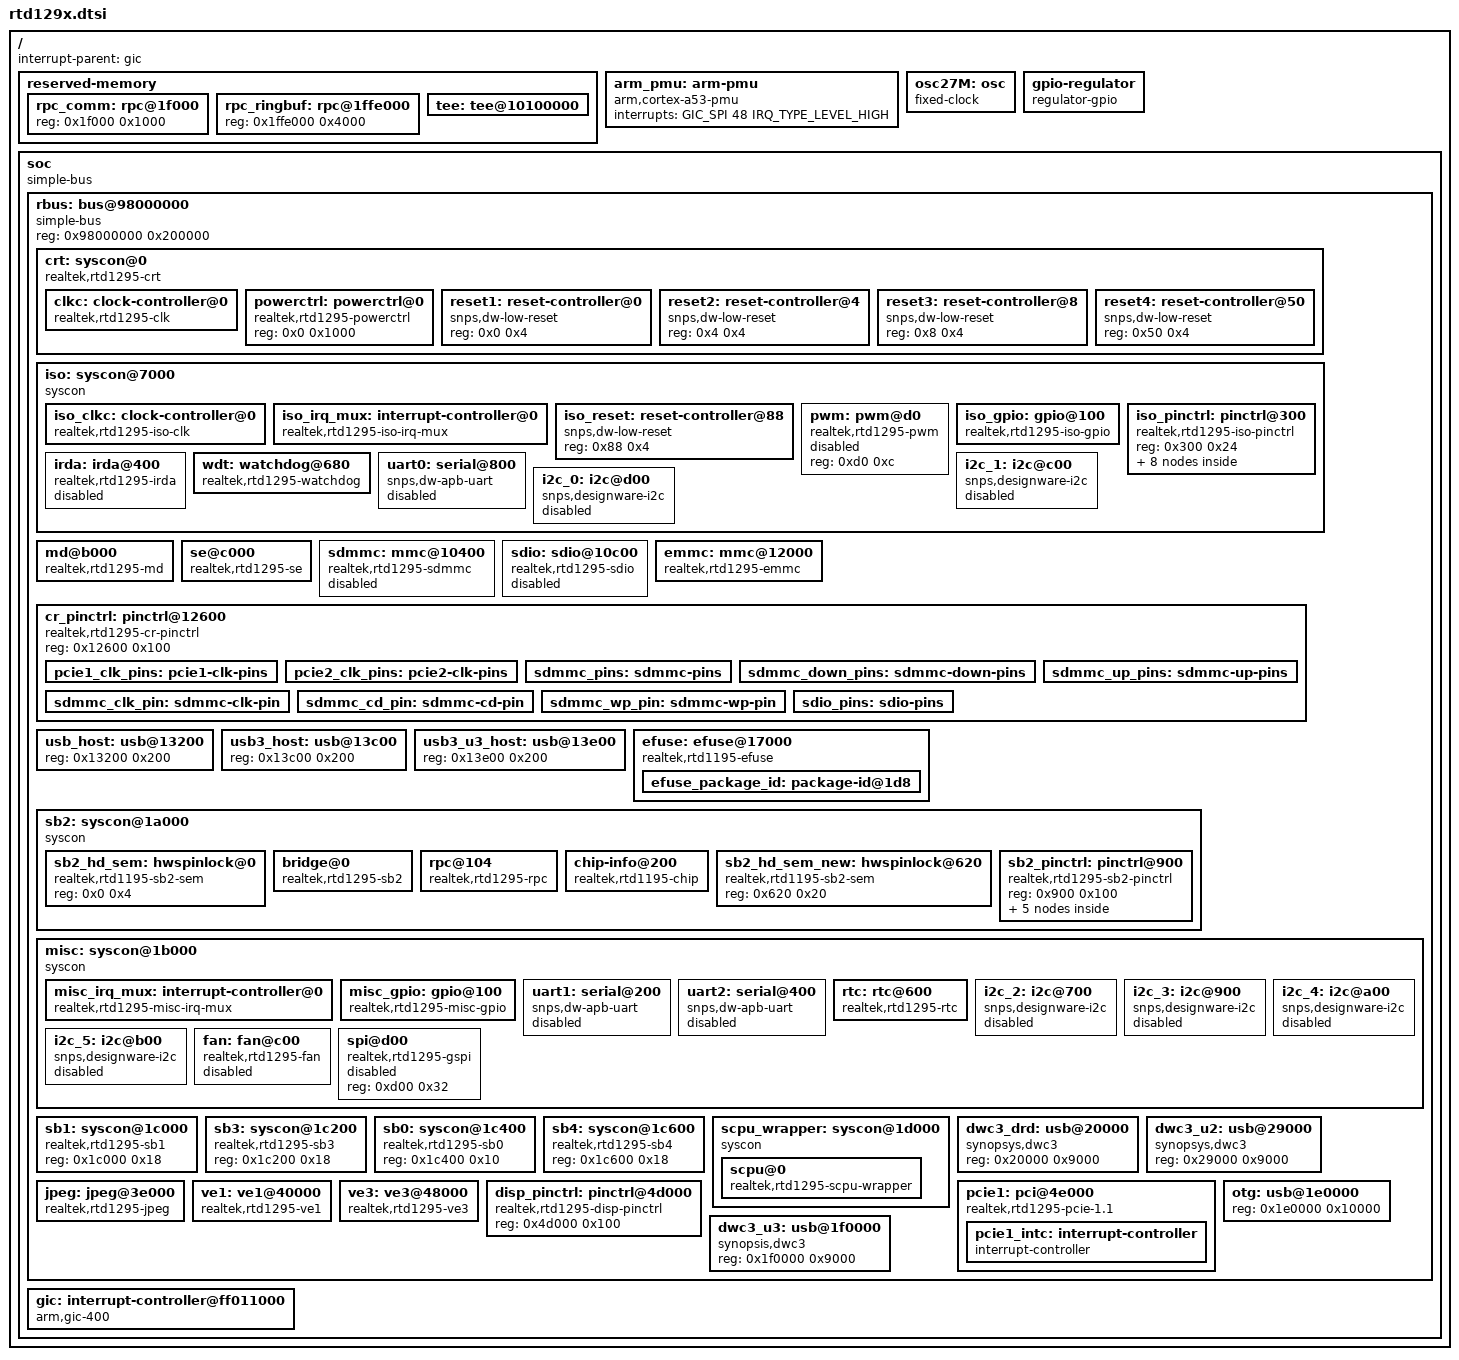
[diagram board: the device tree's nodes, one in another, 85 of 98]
// SPDX-License-Identifier: (GPL-2.0-or-later OR BSD-2-Clause)
/*
 * Realtek RTD1293/RTD1295/RTD1296 SoC
 *
 * Copyright (c) 2016-2019 Andreas Färber
 */

/memreserve/	0x0000000000000000 0x000000000001f000;
/memreserve/	0x000000000001f000 0x00000000000e1000;
/memreserve/	0x0000000001b00000 0x00000000004be000;

#include <dt-bindings/clock/realtek,rtd1295.h>
#include <dt-bindings/gpio/gpio.h>
#include <dt-bindings/interrupt-controller/arm-gic.h>
#include <dt-bindings/reset/realtek,rtd1295.h>

/ {
	interrupt-parent = <&gic>;
	#address-cells = <1>;
	#size-cells = <1>;

	reserved-memory {
		#address-cells = <1>;
		#size-cells = <1>;
		ranges;

		rpc_comm: rpc@1f000 {
			reg = <0x1f000 0x1000>;
		};

		rpc_ringbuf: rpc@1ffe000 {
			reg = <0x1ffe000 0x4000>;
		};

		tee: tee@10100000 {
			reg = <0x10100000 0xf00000>;
			no-map;
		};
	};

	arm_pmu: arm-pmu {
		compatible = "arm,cortex-a53-pmu";
		interrupts = <GIC_SPI 48 IRQ_TYPE_LEVEL_HIGH>;
	};

	osc27M: osc {
		compatible = "fixed-clock";
		clock-frequency = <27000000>;
		#clock-cells = <0>;
		clock-output-names = "osc27M";
	};

	gpio-regulator {
		compatible = "regulator-gpio";
		regulator-type = "voltage";
		regulator-name = "gpio-regulator";
		regulator-min-microvolt = < 850000>;
		regulator-max-microvolt = <1050000>;
		regulator-boot-on;
		regulator-always-on;
		gpios = <&iso_gpio 16 GPIO_ACTIVE_HIGH>,
			<&iso_gpio 17 GPIO_ACTIVE_HIGH>;
		gpios-states = <0>, <1>;
		enable-active-high;
		states = < 850000 0>,
			 < 950000 2>,
			 <1050000 3>;
	};

	soc {
		compatible = "simple-bus";
		#address-cells = <1>;
		#size-cells = <1>;
		ranges = <0x00000000 0x00000000 0x0001f000>, /* boot ROM */
			 <0x00030000 0x00030000 0x00020000>, /* PCIe IO */
			 /* Exclude up to 2 GiB of RAM */
			 <0x80000000 0x80000000 0x80000000>;

		rbus: bus@98000000 {
			compatible = "simple-bus";
			reg = <0x98000000 0x200000>;
			#address-cells = <1>;
			#size-cells = <1>;
			ranges = <0x00000000 0x98000000 0x00200000>,
				 <0xc0000000 0xc0000000 0x02000000>, /* PCIe */
				 <0x10030000 0x00030000 0x00020000>; /* PCIe */

			crt: syscon@0 {
				compatible = "realtek,rtd1295-crt", "syscon", "simple-mfd";
				reg = <0x0 0x1800>;
				reg-io-width = <4>;
				#address-cells = <1>;
				#size-cells = <1>;
				ranges = <0x0 0x0 0x1800>;
			};

			iso: syscon@7000 {
				compatible = "syscon", "simple-mfd";
				reg = <0x7000 0x1000>;
				reg-io-width = <4>;
				#address-cells = <1>;
				#size-cells = <1>;
				ranges = <0x0 0x7000 0x1000>;
			};

			md@b000 {
				compatible = "realtek,rtd1295-md";
				reg = <0xb000 0x1000>;
				interrupts = <GIC_SPI 38 IRQ_TYPE_LEVEL_HIGH>;
			};

			se@c000 {
				compatible = "realtek,rtd1295-se";
				reg = <0xc000 0x1000>;
				interrupts = <GIC_SPI 20 IRQ_TYPE_LEVEL_HIGH>;
			};

			sdmmc: mmc@10400 {
				compatible = "realtek,rtd1295-sdmmc";
				reg = <0x10400 0x200>;
				crt-syscon = <&crt>;
				sb2-syscon = <&sb2>;
				pinctrl-names = "default", "card";
				pinctrl-0 = <&sdmmc_pins>, <&sdmmc_down_pins>, <&sdmmc_clk_pin>, <&sdmmc_cd_pin>, <&sdmmc_wp_pin>;
				pinctrl-1 = <&sdmmc_pins>, <&sdmmc_up_pins>, <&sdmmc_clk_pin>, <&sdmmc_cd_pin>, <&sdmmc_wp_pin>;
				interrupts = <GIC_SPI 44 IRQ_TYPE_LEVEL_HIGH>;
				resets = <&reset2 RTD1295_RSTN_CR>;
				clocks = <&clkc RTD1295_CLK_EN_CR>, <&clkc RTD1295_CLK_EN_SD_IP>;
				clock-names = "clk_en_cr", "clk_en_sd_ip";
				cap-mmc-highspeed;
				cap-sd-highspeed;
				cap-mmc-hw-reset;
				no-sdio;
				sd-uhs-sdr12;
				sd-uhs-sdr25;
				sd-uhs-sdr50;
				sd-uhs-sdr104;
				status = "disabled";
			};

			sdio: sdio@10c00 {
				compatible = "realtek,rtd1295-sdio";
				reg = <0x10c00 0x100>,
				      <0x10a00 0x100>; /* wrapper */
				crt-syscon = <&crt>;
				pinctrl-names = "default";
				pinctrl-0 = <&sdio_pins>;
				interrupts = <GIC_SPI 45 IRQ_TYPE_LEVEL_HIGH>;
				resets = <&reset2 RTD1295_RSTN_SDIO>;
				clocks = <&clkc RTD1295_CLK_EN_SDIO>, <&clkc RTD1295_CLK_EN_SDIO_IP>;
				clock-names = "clk_en_sdio", "clk_en_sdio_ip";
				cap-mmc-highspeed;
				cap-sd-highspeed;
				cap-sdio-irq;
				no-mmc;
				no-sd;
				sd-uhs-sdr12;
				sd-uhs-sdr25;
				sd-uhs-sdr50;
				sd-uhs-sdr104;
				status = "disabled";
			};

			emmc: mmc@12000 {
				compatible = "realtek,rtd1295-emmc";
				reg = <0x12000 0xa00>;
				interrupts = <GIC_SPI 42 IRQ_TYPE_LEVEL_HIGH>;
			};

			cr_pinctrl: pinctrl@12600 {
				compatible = "realtek,rtd1295-cr-pinctrl";
				reg = <0x12600 0x100>;
			};

			usb_host: usb@13200 {
				reg = <0x13200 0x200>;
			};

			usb3_host: usb@13c00 {
				reg = <0x13c00 0x200>;
			};

			usb3_u3_host: usb@13e00 {
				reg = <0x13e00 0x200>;
			};

			efuse: efuse@17000 {
				compatible = "realtek,rtd1195-efuse";
				reg = <0x17000 0x400>;
				read-only;
				#address-cells = <1>;
				#size-cells = <1>;
			};

			sb2: syscon@1a000 {
				compatible = "syscon", "simple-mfd";
				reg = <0x1a000 0x1000>;
				reg-io-width = <4>;
				#address-cells = <1>;
				#size-cells = <1>;
				ranges = <0x0 0x1a000 0x1000>;
			};

			misc: syscon@1b000 {
				compatible = "syscon", "simple-mfd";
				reg = <0x1b000 0x1000>;
				reg-io-width = <4>;
				#address-cells = <1>;
				#size-cells = <1>;
				ranges = <0x0 0x1b000 0x1000>;
			};

			sb1: syscon@1c000 {
				compatible = "realtek,rtd1295-sb1";
				reg = <0x1c000 0x18>;
			};

			sb3: syscon@1c200 {
				compatible = "realtek,rtd1295-sb3";
				reg = <0x1c200 0x18>;
			};

			sb0: syscon@1c400 {
				compatible = "realtek,rtd1295-sb0";
				reg = <0x1c400 0x10>;
			};

			sb4: syscon@1c600 {
				compatible = "realtek,rtd1295-sb4", "syscon";
				reg = <0x1c600 0x18>;
			};

			scpu_wrapper: syscon@1d000 {
				compatible = "syscon", "simple-mfd";
				reg = <0x1d000 0x2000>;
				reg-io-width = <4>;
				#address-cells = <1>;
				#size-cells = <1>;
				ranges = <0x0 0x1d000 0x2000>;
			};

			dwc3_drd: usb@20000 {
				compatible = "synopsys,dwc3";
				reg = <0x20000 0x9000>;
			};

			dwc3_u2: usb@29000 {
				compatible = "synopsys,dwc3";
				reg = <0x29000 0x9000>;
			};

			jpeg: jpeg@3e000 {
				compatible = "realtek,rtd1295-jpeg";
				reg = <0x3e000 0x1000>;
				interrupts = <GIC_SPI 52 IRQ_TYPE_LEVEL_HIGH>;
			};

			ve1: ve1@40000 {
				compatible = "realtek,rtd1295-ve1";
				reg = <0x40000 0x8000>;
				interrupts = <GIC_SPI 53 IRQ_TYPE_LEVEL_HIGH>,
				             <GIC_SPI 54 IRQ_TYPE_LEVEL_HIGH>;
			};

			ve3: ve3@48000 {
				compatible = "realtek,rtd1295-ve3";
				reg = <0x48000 0x4000>;
				interrupts = <GIC_SPI 55 IRQ_TYPE_LEVEL_HIGH>;
			};

			disp_pinctrl: pinctrl@4d000 {
				compatible = "realtek,rtd1295-disp-pinctrl";
				reg = <0x4d000 0x100>;
			};

			pcie1: pci@4e000 {
				device_type = "pci";
				compatible = "realtek,rtd1295-pcie-1.1";
				reg = <0x4e000 0x1000>,
				      <0x4f000 0x1000>,
				      <0xc0000000 0x01000000>;
				pinctrl-names = "default";
				pinctrl-0 = <&pcie1_clk_pins>;
				sb4-syscon = <&sb4>;
				clocks = <&clkc RTD1295_CLK_EN_PCIE0>;
				resets = <&reset2 RTD1295_RSTN_PCIE0>,
					 <&reset2 RTD1295_RSTN_PCIE0_CORE>,
					 <&reset2 RTD1295_RSTN_PCIE0_POWER>,
					 <&reset2 RTD1295_RSTN_PCIE0_STITCH>,
					 <&reset2 RTD1295_RSTN_PCIE0_NONSTICH>,
					 <&reset2 RTD1295_RSTN_PCIE0_PHY>,
					 <&reset4 RTD1295_RSTN_PCIE0_PHY_MDIO>;
				reset-names = "pcie",
					      "pcie_core",
					      "pcie_power",
					      "pcie_stitch",
					      "pcie_nonstitch",
					      "pcie_phy",
					      "pcie_phy_mdio";
				reset-gpios = <&misc_gpio 18 GPIO_ACTIVE_LOW>;
				interrupts = <GIC_SPI 61 IRQ_TYPE_LEVEL_HIGH>;
				#interrupt-cells = <1>;
				interrupt-map-mask = <0 0 0 7>;
				interrupt-map = <0 0 0 1 &pcie1_intc 0>,
						<0 0 0 2 &pcie1_intc 1>,
						<0 0 0 3 &pcie1_intc 2>,
						<0 0 0 4 &pcie1_intc 3>;
				bus-range = <0x00 0xff>;
				num-lanes = <1>;
				max-link-speed = <1>;
				linux,pci-domain = <0>;
				#address-cells = <3>;
				#size-cells = <2>;
				ranges = <0x02000000 0x00000000 0xc0000000  0xc0000000  0x00000000 0x00001000>,
					 <0x01000000 0x00000000 0x00030000  0x10030000  0x00000000 0x00010000>;

				pcie1_intc: interrupt-controller {
					interrupt-controller;
					#interrupt-cells = <1>;
				};
			};

			otg: usb@1e0000 {
				reg = <0x1e0000 0x10000>;
			};

			dwc3_u3: usb@1f0000 {
				compatible = "synopsis,dwc3";
				reg = <0x1f0000 0x9000>;
			};
		};

		gic: interrupt-controller@ff011000 {
			compatible = "arm,gic-400";
			reg = <0xff011000 0x1000>,
			      <0xff012000 0x2000>,
			      <0xff014000 0x2000>,
			      <0xff016000 0x2000>;
			interrupts = <GIC_PPI 9 (GIC_CPU_MASK_SIMPLE(4) | IRQ_TYPE_LEVEL_LOW)>;
			interrupt-controller;
			#interrupt-cells = <3>;
		};
	};
};

&cr_pinctrl {
	pcie1_clk_pins: pcie1-clk-pins {
		function = "pcie";
		pins = "pcie_clkreq_0";
	};

	pcie2_clk_pins: pcie2-clk-pins {
		function = "pcie";
		pins = "pcie_clkreq_1";
	};

	sdmmc_pins: sdmmc-pins {
		function = "sd_card";
		groups = "mmc_cmd", "mmc_data_0", "mmc_data_1", "mmc_data_2", "mmc_data_3";
	};

	sdmmc_down_pins: sdmmc-down-pins {
		pins = "mmc_cmd", "mmc_data_0", "mmc_data_1", "mmc_data_2", "mmc_data_3";
		bias-pull-down;
	};

	sdmmc_up_pins: sdmmc-up-pins {
		pins = "mmc_cmd", "mmc_data_0", "mmc_data_1", "mmc_data_2", "mmc_data_3";
		bias-pull-up;
	};

	sdmmc_clk_pin: sdmmc-clk-pin {
		pins = "mmc_clk";
		function = "sd_card";
		bias-pull-down;
	};

	sdmmc_cd_pin: sdmmc-cd-pin {
		function = "sd_card";
		groups = "mmc_cd";
		bias-pull-up;
		drive-strength = <4>;
	};

	sdmmc_wp_pin: sdmmc-wp-pin {
		function = "sd_card";
		groups = "mmc_wp";
		bias-pull-up;
		drive-strength = <4>;
	};

	sdio_pins: sdio-pins {
		function = "sdio_0";
		groups = "sdio_cmd", "sdio_clk", "sdio_data_0", "sdio_data_1", "sdio_data_2", "sdio_data_3";
	};
};

&crt {
	clkc: clock-controller@0 {
		compatible = "realtek,rtd1295-clk";
		reg = <0x0 0x1000>;
		clocks = <&osc27M>;
		#clock-cells = <1>;
	};

	powerctrl: powerctrl@0 {
		compatible = "realtek,rtd1295-powerctrl";
		reg = <0x0 0x1000>;
		#power-domain-cells = <1>;
	};

	reset1: reset-controller@0 {
		compatible = "snps,dw-low-reset";
		reg = <0x0 0x4>;
		#reset-cells = <1>;
	};

	reset2: reset-controller@4 {
		compatible = "snps,dw-low-reset";
		reg = <0x4 0x4>;
		#reset-cells = <1>;
	};

	reset3: reset-controller@8 {
		compatible = "snps,dw-low-reset";
		reg = <0x8 0x4>;
		#reset-cells = <1>;
	};

	reset4: reset-controller@50 {
		compatible = "snps,dw-low-reset";
		reg = <0x50 0x4>;
		#reset-cells = <1>;
	};
};

&efuse {
	efuse_package_id: package-id@1d8 {
		reg = <0x1d8 0x1>;
		bits = <0 2>;
	};
};

&iso {
	iso_clkc: clock-controller@0 {
		compatible = "realtek,rtd1295-iso-clk";
		reg = <0x0 0x100>;
		clocks = <&osc27M>;
		#clock-cells = <1>;
	};

	iso_irq_mux: interrupt-controller@0 {
		compatible = "realtek,rtd1295-iso-irq-mux";
		reg = <0x0 0x100>;
		interrupts = <GIC_SPI 41 IRQ_TYPE_LEVEL_HIGH>;
		interrupt-controller;
		#interrupt-cells = <1>;
	};

	iso_reset: reset-controller@88 {
		compatible = "snps,dw-low-reset";
		reg = <0x88 0x4>;
		#reset-cells = <1>;
	};

	pwm: pwm@d0 {
		compatible = "realtek,rtd1295-pwm";
		reg = <0xd0 0xc>;
		status = "disabled";
	};

	iso_gpio: gpio@100 {
		compatible = "realtek,rtd1295-iso-gpio";
		reg = <0x100 0x100>;
		gpio-controller;
		gpio-ranges = <&iso_pinctrl 0 0 35>;
		#gpio-cells = <2>;

		interrupt-parent = <&iso_irq_mux>;
		interrupts = <19>, <20>;
		interrupt-controller;
		#interrupt-cells = <1>;
	};

	iso_pinctrl: pinctrl@300 {
		compatible = "realtek,rtd1295-iso-pinctrl";
		reg = <0x300 0x24>;

		etn_led_pins: etn-led-pins {
			function = "etn_led";
			groups = "etn_led_link", "etn_led_rxtx";
		};

		i2c0_pins: i2c0-pins {
			function = "i2c0";
			groups = "i2c0";
		};

		i2c1_pins: i2c1-pins {
			function = "i2c1";
			groups = "i2c1";
		};

		i2c6_pins: i2c5-pins {
			function = "i2c6";
			groups = "i2c6";
		};

		uart0_pins: uart0-pins {
			function = "uart0";
			groups = "uart0";
		};

		uart1_pins: uart1-pins {
			function = "uart1";
			groups = "uart1";
		};

		uart2_0_pins: uart2-0-pins {
			function = "uart2_0";
			groups = "uart2_0";
		};

		uart2_1_pins: uart2-1-pins {
			function = "uart2_1";
			groups = "uart2_1";
		};
	};

	irda: irda@400 {
		compatible = "realtek,rtd1295-irda";
		reg = <0x400 0x100>;
		interrupt-parent = <&iso_irq_mux>;
		interrupts = <5>;
		status = "disabled";
	};

	wdt: watchdog@680 {
		compatible = "realtek,rtd1295-watchdog";
		reg = <0x680 0x100>;
		clocks = <&osc27M>;
	};

	uart0: serial@800 {
		compatible = "snps,dw-apb-uart";
		reg = <0x800 0x400>;
		reg-shift = <2>;
		reg-io-width = <4>;
		pinctrl-names = "default";
		pinctrl-0 = <&uart0_pins>;
		clocks = <&iso_clkc RTD1295_ISO_CLK_EN_MISC_UR0>;
		resets = <&iso_reset RTD1295_ISO_RSTN_UR0>;
		interrupt-parent = <&iso_irq_mux>;
		interrupts = <2>;
		status = "disabled";
	};

	i2c_1: i2c@c00 {
		compatible = "snps,designware-i2c";
		reg = <0xc00 0x100>;
		pinctrl-names = "default";
		pinctrl-0 = <&i2c1_pins>;
		clocks = <&iso_clkc RTD1295_ISO_CLK_EN_I2C_1>;
		resets = <&iso_reset RTD1295_ISO_RSTN_I2C_1>;
		interrupt-parent = <&iso_irq_mux>;
		interrupts = <11>;
		#address-cells = <1>;
		#size-cells = <0>;
		status = "disabled";
	};

	i2c_0: i2c@d00 {
		compatible = "snps,designware-i2c";
		reg = <0xd00 0x100>;
		pinctrl-names = "default";
		pinctrl-0 = <&i2c0_pins>;
		clocks = <&iso_clkc RTD1295_ISO_CLK_EN_I2C_0>;
		resets = <&iso_reset RTD1295_ISO_RSTN_I2C_0>;
		interrupt-parent = <&iso_irq_mux>;
		interrupts = <8>;
		#address-cells = <1>;
		#size-cells = <0>;
		status = "disabled";
	};
};

&misc {
	misc_irq_mux: interrupt-controller@0 {
		compatible = "realtek,rtd1295-misc-irq-mux";
		reg = <0x0 0x100>;
		interrupts = <GIC_SPI 40 IRQ_TYPE_LEVEL_HIGH>;
		interrupt-controller;
		#interrupt-cells = <1>;
	};

	misc_gpio: gpio@100 {
		compatible = "realtek,rtd1295-misc-gpio";
		reg = <0x100 0x100>;
		gpio-controller;
		gpio-ranges = <&sb2_pinctrl   0 0 54>,
			      <&disp_pinctrl 54 0 10>,
			      <&cr_pinctrl   64 0 37>;
		#gpio-cells = <2>;

		interrupt-parent = <&misc_irq_mux>;
		interrupts = <19>, <20>;
		interrupt-controller;
		#interrupt-cells = <1>;
	};

	uart1: serial@200 {
		compatible = "snps,dw-apb-uart";
		reg = <0x200 0x100>;
		reg-shift = <2>;
		reg-io-width = <4>;
		pinctrl-names = "default";
		pinctrl-0 = <&uart1_pins>;
		clocks = <&clkc RTD1295_CLK_EN_UR1>;
		resets = <&reset2 RTD1295_RSTN_UR1>;
		interrupt-parent = <&misc_irq_mux>;
		interrupts = <3>;
		status = "disabled";
	};

	uart2: serial@400 {
		compatible = "snps,dw-apb-uart";
		reg = <0x400 0x100>;
		reg-shift = <2>;
		reg-io-width = <4>;
		clocks = <&clkc RTD1295_CLK_EN_UR2>;
		resets = <&reset2 RTD1295_RSTN_UR2>;
		interrupt-parent = <&misc_irq_mux>;
		interrupts = <8>;
		status = "disabled";
	};

	rtc: rtc@600 {
		compatible = "realtek,rtd1295-rtc";
		reg = <0x600 0x100>;
		clocks = <&clkc RTD1295_CLK_EN_MISC_RTC>;
	};

	i2c_2: i2c@700 {
		compatible = "snps,designware-i2c";
		reg = <0x700 0x100>;
		pinctrl-names = "default";
		pinctrl-0 = <&i2c2_pins>;
		clocks = <&clkc RTD1295_CLK_EN_MISC_I2C_2>;
		interrupt-parent = <&misc_irq_mux>;
		interrupts = <26>;
		#address-cells = <1>;
		#size-cells = <0>;
		status = "disabled";
	};

	i2c_3: i2c@900 {
		compatible = "snps,designware-i2c";
		reg = <0x900 0x100>;
		pinctrl-names = "default";
		pinctrl-0 = <&i2c3_pins>;
		clocks = <&clkc RTD1295_CLK_EN_MISC_I2C_3>;
		interrupt-parent = <&misc_irq_mux>;
		interrupts = <23>;
		#address-cells = <1>;
		#size-cells = <0>;
		status = "disabled";
	};

	i2c_4: i2c@a00 {
		compatible = "snps,designware-i2c";
		reg = <0xa00 0x100>;
		pinctrl-names = "default";
		pinctrl-0 = <&i2c4_pins>;
		clocks = <&clkc RTD1295_CLK_EN_MISC_I2C_4>;
		interrupt-parent = <&misc_irq_mux>;
		interrupts = <15>;
		#address-cells = <1>;
		#size-cells = <0>;
		status = "disabled";
	};

	i2c_5: i2c@b00 {
		compatible = "snps,designware-i2c";
		reg = <0xb00 0x100>;
		pinctrl-names = "default";
		pinctrl-0 = <&i2c5_pins>;
		clocks = <&clkc RTD1295_CLK_EN_MISC_I2C_5>;
		interrupt-parent = <&misc_irq_mux>;
		interrupts = <14>;
		#address-cells = <1>;
		#size-cells = <0>;
		status = "disabled";
	};

	fan: fan@c00 {
		compatible = "realtek,rtd1295-fan";
		reg = <0xc00 0x14>;
		interrupt-parent = <&misc_irq_mux>;
		interrupts = <29>;
		status = "disabled";
	};

	spi@d00 {
		compatible = "realtek,rtd1295-gspi";
		reg = <0xd00 0x32>;
		status = "disabled";
	};
};

&sb2 {
	sb2_hd_sem: hwspinlock@0 {
		compatible = "realtek,rtd1195-sb2-sem";
		reg = <0x0 0x4>;
		#hwlock-cells = <0>;
	};

	bridge@0 {
		compatible = "realtek,rtd1295-sb2";
		reg = <0x0 0x100>;
		interrupts = <GIC_SPI 36 IRQ_TYPE_LEVEL_HIGH>;
	};

	rpc@104 {
		compatible = "realtek,rtd1295-rpc";
		reg = <0x104 0xc>;
		memory-region = <&rpc_comm>, <&rpc_ringbuf>;
		interrupts = <GIC_SPI 33 IRQ_TYPE_LEVEL_HIGH>;
	};

	chip-info@200 {
		compatible = "realtek,rtd1195-chip";
		reg = <0x200 0x8>;
		iso-syscon = <&iso>;
		nvmem-cells = <&efuse_package_id>;
		nvmem-cell-names = "efuse_package_id";
	};

	sb2_hd_sem_new: hwspinlock@620 {
		compatible = "realtek,rtd1195-sb2-sem";
		reg = <0x620 0x20>;
		#hwlock-cells = <1>;
	};

	sb2_pinctrl: pinctrl@900 {
		compatible = "realtek,rtd1295-sb2-pinctrl";
		reg = <0x900 0x100>;

		i2c2_pins: i2c2-pins {
			function = "i2c2";
			groups = "tp1_sync", "tp1_clk";
		};

		i2c3_pins: i2c3-pins {
			function = "i2c3";
			groups = "tp1_data", "tp1_valid";
		};

		i2c4_pins: i2c4-pins {
			function = "i2c4";
			groups = "i2c_scl_4", "i2c_sda_4";
		};

		i2c5_pins: i2c5-pins {
			function = "i2c5";
			groups = "i2c_scl_5", "i2c_sda_5";
		};

		rgmii0_pins: rgmii0-pins {
			function = "rgmii";
			groups = "rgmii0_txc", "rgmii0_tx_ctl",
				 "rgmii0_txd_0", "rgmii0_txd_1", "rgmii0_txd_2", "rgmii0_txd_3",
				 "rgmii0_rxc", "rgmii0_rx_ctl",
				 "rgmii0_rxd_0", "rgmii0_rxd_1", "rgmii0_rxd_2", "rgmii0_rxd_3",
				 "rgmii0_mdio", "rgmii0_mdc";
		};
	};
};

&scpu_wrapper {
	scpu@0 {
		compatible = "realtek,rtd1295-scpu-wrapper";
		reg = <0x0 0x500>;
		interrupts = <GIC_SPI 46 IRQ_TYPE_LEVEL_HIGH>;
	};
};
